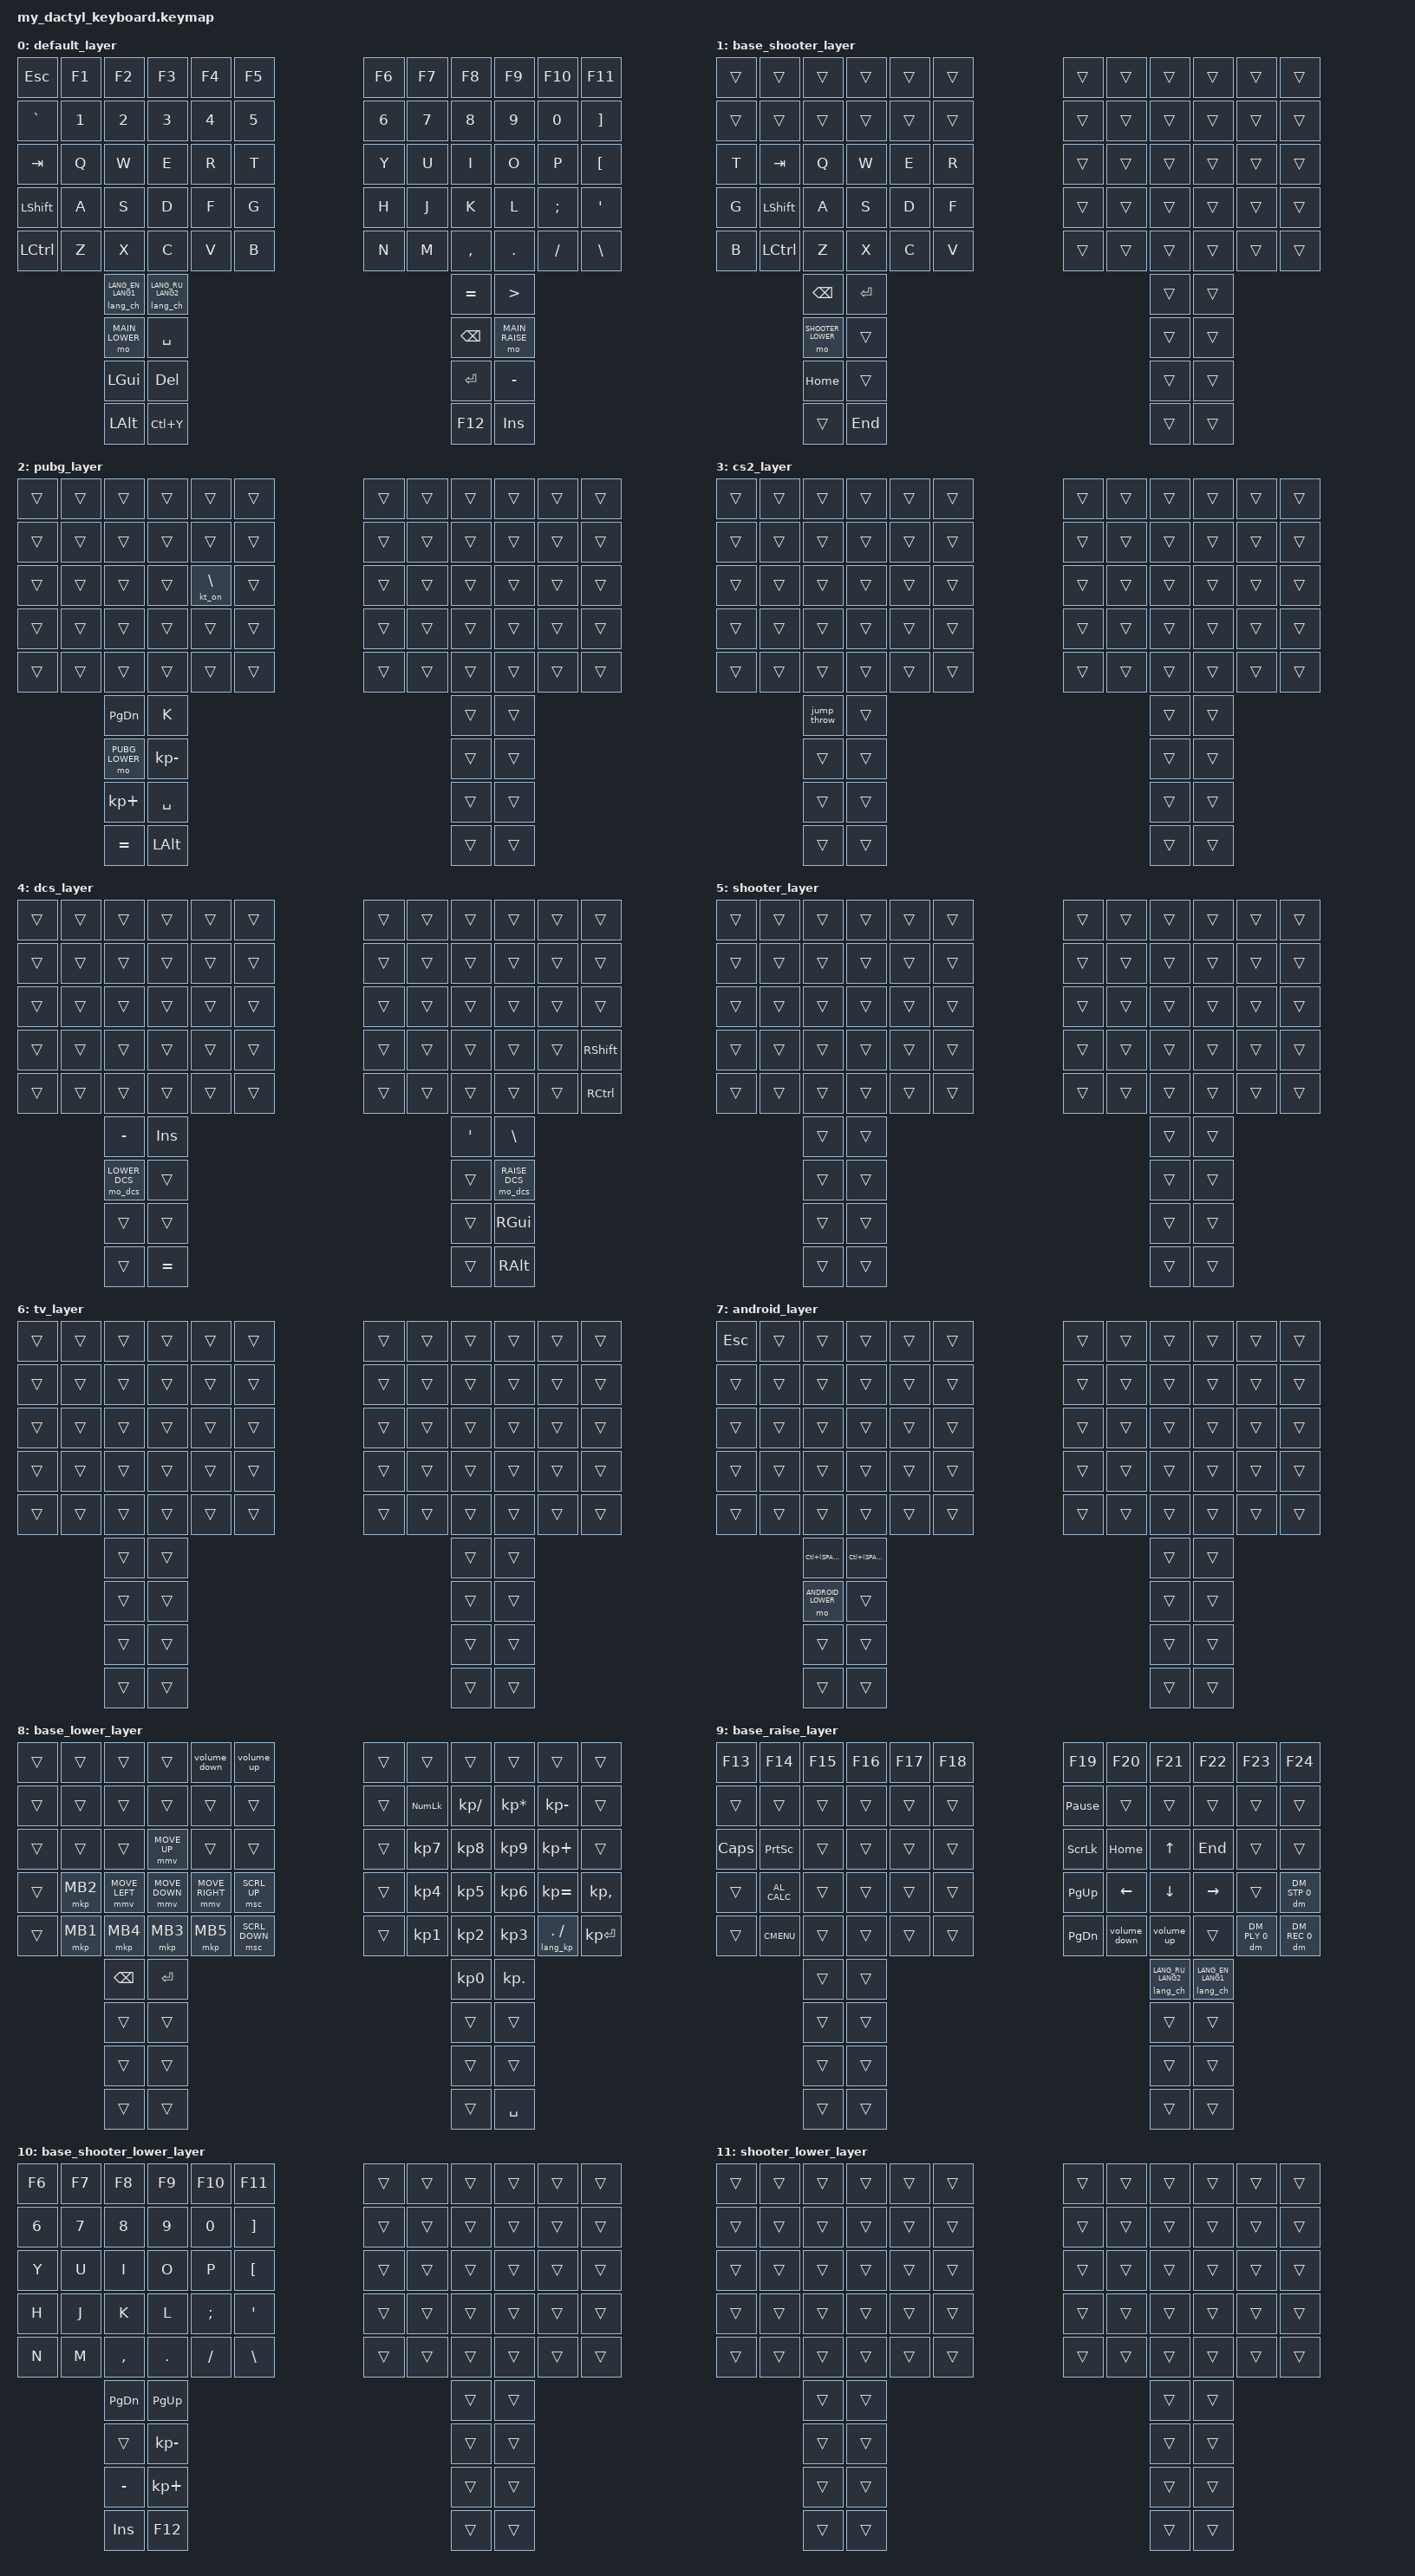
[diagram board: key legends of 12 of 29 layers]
/*
 * Copyright (c) 2020 The ZMK Contributors
 *
 * SPDX-License-Identifier: MIT
 */

#include <behaviors.dtsi>
#include <dt-bindings/zmk/keys.h>
#include <dt-bindings/zmk/bt.h>
#include <dt-bindings/zmk/rgb.h>
#include <dt-bindings/zmk/ext_power.h>
#include <dt-bindings/zmk/outputs.h>
#include <dt-bindings/zmk/backlight.h>
#include <dt-bindings/zmk/language.h>
#include <dt-bindings/zmk/dynamic_macro.h>

#define ZMK_POINTING_DEFAULT_MOVE_VAL 1500
#define ZMK_POINTING_DEFAULT_SCRL_VAL 40    // default: 10

#include <dt-bindings/zmk/pointing.h>

#define BASE                  0
#define BASE_SHOOTER          1
#define PUBG                  2
#define CS2                   3
#define DCS                   4
#define SHOOTER               5
#define TV_LAYER              6
#define ANDROID               7
#define LOWER                 8
#define RAISE                 9
#define BASE_SHOOTER_LOWER    10
#define SHOOTER_LOWER         11
#define MAIN_LOWER            12
#define MAIN_RAISE            13
#define PUBG_LOWER            14
#define TV_LOWER_LAYER        15
#define ANDROID_LOWER         16
#define LOWER_DCS             17
#define RAISE_DCS             18
#define RAISE_LOWER_DCS       19
#define RAISE_LOWER_DCS_ALT   20
#define RAISE_LOWER_DCS_GUI   21
#define RAISE_LOWER_DCS_CTRL  22
#define RAISE_LOWER_DCS_SHFT  23
#define RAISE_LOWER_DCS_CS    24
#define RAISE_LOWER_DCS_GA    25
#define SC2                   26
#define SC2_LOWER             27
#define ADJUST                28

/ {
    conditional_layers {
        compatible = "zmk,conditional-layers";
        adjust_layer {
            if-layers = <LOWER RAISE>;
            then-layer = <ADJUST>;
        };
        adjust_pubg_layer {
            if-layers = <PUBG_LOWER RAISE>;
            then-layer = <ADJUST>;
        };
        adjust_shooter_layer {
            if-layers = <SHOOTER_LOWER RAISE>;
            then-layer = <ADJUST>;
        };
        adjust_sc2_layer {
            if-layers = <SC2_LOWER RAISE>;
            then-layer = <ADJUST>;
        };
        lower_tv_layer {
            if-layers = <TV_LOWER_LAYER>;
            then-layer = <LOWER>;
        };
        lower_dcs_layer {
            if-layers = <LOWER_DCS>;
            then-layer = <LOWER>;
        };
        raise_dcs_layer {
            if-layers = <RAISE_DCS>;
            then-layer = <RAISE>;
        };
        lower_layer {
            if-layers = <MAIN_LOWER>;
            then-layer = <LOWER>;
        };
        android_lower_layer {
            if-layers = <ANDROID_LOWER>;
            then-layer = <LOWER>;
        };
        sc2_layer {
            if-layers = <SC2>;
            then-layer = <BASE_SHOOTER>;
        };
        sc2_lower_layer {
            if-layers = <SC2_LOWER>;
            then-layer = <BASE_SHOOTER_LOWER>;
        };
        raise_layer {
            if-layers = <MAIN_RAISE>;
            then-layer = <RAISE>;
        };
        pubg_layer {
            if-layers = <PUBG>;
            then-layer = <BASE_SHOOTER>;
        };
        cs2_layer {
            if-layers = <CS2>;
            then-layer = <BASE_SHOOTER>;
        };
        shooter_layer {
            if-layers = <SHOOTER>;
            then-layer = <BASE_SHOOTER>;
        };
        shooter_lower_layer {
            if-layers = <SHOOTER_LOWER>;
            then-layer = <BASE_SHOOTER_LOWER>;
        };
    };

    behaviors {
        hidiokp: hid_io_key_press {
          compatible = "zmk,behavior-hid-io-key-press";
          #binding-cells = <1>;
        };
        tog_on: toggle_layer_on_only {
            compatible = "zmk,behavior-toggle-layer";
            #binding-cells = <1>;
            display-name = "Toggle Layer On";
            toggle-mode = "on";
        };
        tog_off: toggle_layer_off_only {
            compatible = "zmk,behavior-toggle-layer";
            #binding-cells = <1>;
            display-name = "Toggle Layer Off";
            toggle-mode = "off";
        };
        kt_off: key_toggle_off_only {
            compatible = "zmk,behavior-key-toggle";
            #binding-cells = <1>;
            display-name = "Key Toggle Off";
            toggle-mode = "off";
        };
        kt_on: key_toggle_on_only {
            compatible = "zmk,behavior-key-toggle";
            #binding-cells = <1>;
            display-name = "Key Toggle On";
            toggle-mode = "on";
        };
        z2m: z2m {
            compatible = "zmk,behavior-zigbee-command";
            #binding-cells = <1>;
            display-name = "Zigbee command";
        };
        z2m_on: z2m_on {
            compatible = "zmk,behavior-zigbee-start";
            #binding-cells = <0>;
            display-name = "Start Zigbee";
        };
    };

    macros {
        hidlm: hidlm {
            compatible = "zmk,behavior-macro-two-param";
            wait-ms = <0>;
            tap-ms = <0>;
            #binding-cells = <2>;
            bindings
                = <&macro_param_1to1>
                , <&macro_press &mo MACRO_PLACEHOLDER>
                , <&macro_param_2to1>
                , <&macro_press &hidiokp MACRO_PLACEHOLDER>
                , <&macro_pause_for_release>
                , <&macro_param_2to1>
                , <&macro_release &hidiokp MACRO_PLACEHOLDER>
                , <&macro_param_1to1>
                , <&macro_release &mo MACRO_PLACEHOLDER>
                ;
        };
        skm: sticky_modifiers {
            compatible = "zmk,behavior-sticky-key";
            #binding-cells = <1>;
            bindings = <&kp>;
            release-after-ms = <2000>;
            ignore-modifiers;
        };
        sw_bl: sw_bl {
            compatible = "zmk,behavior-macro-one-param";
            #binding-cells = <1>;
            bindings
                = <&out OUT_BLE>
                , <&macro_param_1to2>
                , <&bt BT_SEL MACRO_PLACEHOLDER>
                ;
        };
        sw_bl1: sw_bl1 {
            compatible = "zmk,behavior-macro";
            #binding-cells = <0>;
            bindings
                = <&out OUT_BLE>
                , <&to BASE>
                , <&bt BT_SEL 0>
                ;
        };
        sw_bl2: sw_bl2 {
            compatible = "zmk,behavior-macro";
            #binding-cells = <0>;
            bindings
                = <&out OUT_BLE>
                , <&to ANDROID>
                , <&bt BT_SEL 1>
                ;
        };
        jump_throw: jump_throw {
            compatible = "zmk,behavior-macro";
            #binding-cells = <0>;
            bindings
                = <&macro_press &kp SPACE &kp F13 &kp F14>
                , <&macro_pause_for_release>
                , <&macro_release &kp SPACE &kp F13 &kp F14>
                ;
        };
        volume_up: volume_up {
            compatible = "zmk,behavior-macro";
            #binding-cells = <0>;
            bindings
                = <&macro_press &kp K_VOLUME_UP &kp C_VOLUME_UP>
                , <&macro_pause_for_release>
                , <&macro_release &kp K_VOLUME_UP &kp C_VOLUME_UP>
                ;
        };
        volume_down: volume_down {
            compatible = "zmk,behavior-macro";
            #binding-cells = <0>;
            bindings
                = <&macro_press &kp K_VOLUME_DOWN &kp C_VOLUME_DOWN>
                , <&macro_pause_for_release>
                , <&macro_release &kp K_VOLUME_DOWN &kp C_VOLUME_DOWN>
                ;
        };
        mo_dcs: parent_hold_dcs {
             compatible = "zmk,behavior-macro-one-param";
             #binding-cells = <1>;
             wait-ms = <0>;
             tap-ms = <0>;
             bindings
                 = <&macro_param_1to1>
                 , <&macro_press &mo MACRO_PLACEHOLDER>
                 , <&macro_pause_for_release>
                 , <&macro_tap &tog_off RAISE_LOWER_DCS &tog_off RAISE_LOWER_DCS_CTRL &tog_off RAISE_LOWER_DCS_SHFT &tog_off RAISE_LOWER_DCS_CS &tog_off RAISE_LOWER_DCS_GA &tog_off RAISE_LOWER_DCS_ALT &tog_off RAISE_LOWER_DCS_GUI>
                 , <&macro_param_1to1>
                 , <&macro_release &mo MACRO_PLACEHOLDER>
                 ;
        };
        lc_dcs: layer_choose_dcs {
             compatible = "zmk,behavior-macro-one-param";
             #binding-cells = <1>;
             wait-ms = <0>;
             tap-ms = <0>;
             bindings
                 = <&macro_tap &tog_off RAISE_LOWER_DCS_CTRL &tog_off RAISE_LOWER_DCS_SHFT &tog_off RAISE_LOWER_DCS_CS &tog_off RAISE_LOWER_DCS_GA &tog_off RAISE_LOWER_DCS_ALT &tog_off RAISE_LOWER_DCS_GUI>
                 , <&macro_param_1to1>
                 , <&macro_tap &tog_on MACRO_PLACEHOLDER>
                 ;
        };
        hidm: hidm {
              compatible = "zmk,behavior-macro-two-param";
              wait-ms = <20>;
              tap-ms = <20>;
              #binding-cells = <2>;
              bindings
                  = <&macro_param_1to1>
                  , <&macro_press &kp MACRO_PLACEHOLDER>
                  , <&macro_param_2to1>
                  , <&macro_press &hidiokp MACRO_PLACEHOLDER>
                  , <&macro_pause_for_release>
                  , <&macro_param_2to1>
                  , <&macro_release &hidiokp MACRO_PLACEHOLDER>
                  , <&macro_param_1to1>
                  , <&macro_release &kp MACRO_PLACEHOLDER>
                  ;
          };
        slm: sticky_layer_modifier {
            compatible = "zmk,behavior-macro-two-param";
            #binding-cells = <2>;

            wait-ms = <0>;
            tap-ms = <0>;

            bindings
                = <&macro_param_1to1>
                , <&sl MACRO_PLACEHOLDER>

                , <&macro_param_2to1>
                , <&sk MACRO_PLACEHOLDER>
                ;
        };
        sc2_second: sc2_second {
            compatible = "zmk,behavior-macro-one-param";
            #binding-cells = <1>;

            wait-ms = <20>;
            tap-ms = <20>;

            bindings
                = <&macro_param_1to1>
                , <&kp MACRO_PLACEHOLDER>
                , <&kp TAB>
                ;
        };
    };

    keymap {
        compatible = "zmk,keymap";

        default_layer {
            bindings = <
&kp ESC   &kp F1 &kp F2                 &kp F3                 &kp F4 &kp F5                    &kp F6 &kp F7 &kp F8    &kp F9         &kp F10  &kp F11
&kp GRAVE &kp N1 &kp N2                 &kp N3                 &kp N4 &kp N5                    &kp N6 &kp N7 &kp N8    &kp N9         &kp N0   &kp RBKT
&kp TAB   &kp Q  &kp W                  &kp E                  &kp R  &kp T                     &kp Y  &kp U  &kp I     &kp O          &kp P    &kp LBKT
&kp LSHFT &kp A  &kp S                  &kp D                  &kp F  &kp G                     &kp H  &kp J  &kp K     &kp L          &kp SEMI &kp SQT
&kp LCTRL &kp Z  &kp X                  &kp C                  &kp V  &kp B                     &kp N  &kp M  &kp COMMA &kp DOT        &kp FSLH &kp BSLH
                 &lang_ch LANG_EN LANG1 &lang_ch LANG_RU LANG2                                                &kp EQUAL &kp GT
                 &mo MAIN_LOWER         &kp SPACE                                                             &kp BSPC  &mo MAIN_RAISE
                 &kp LGUI               &kp DEL                                                               &kp RET   &kp MINUS
                 &kp LALT               &kp LC(Y)                                                             &kp F12   &kp INS
            >;
        };

        base_shooter_layer {
            bindings = <
&trans &trans    &trans            &trans  &trans &trans                    &trans &trans &trans &trans &trans &trans
&trans &trans    &trans            &trans  &trans &trans                    &trans &trans &trans &trans &trans &trans
&kp T  &kp TAB   &kp Q             &kp W   &kp E  &kp R                     &trans &trans &trans &trans &trans &trans
&kp G  &kp LSHFT &kp A             &kp S   &kp D  &kp F                     &trans &trans &trans &trans &trans &trans
&kp B  &kp LCTRL &kp Z             &kp X   &kp C  &kp V                     &trans &trans &trans &trans &trans &trans
                 &kp BSPC          &kp RET                                                &trans &trans
                 &mo SHOOTER_LOWER &trans                                                 &trans &trans
                 &kp HOME          &trans                                                 &trans &trans
                 &trans            &kp END                                                &trans &trans
            >;
        };

        pubg_layer {
            bindings = <
&trans &trans &trans         &trans       &trans      &trans                    &trans &trans &trans &trans &trans &trans
&trans &trans &trans         &trans       &trans      &trans                    &trans &trans &trans &trans &trans &trans
&trans &trans &trans         &trans       &kt_on BSLH &trans                    &trans &trans &trans &trans &trans &trans
&trans &trans &trans         &trans       &trans      &trans                    &trans &trans &trans &trans &trans &trans
&trans &trans &trans         &trans       &trans      &trans                    &trans &trans &trans &trans &trans &trans
              &kp PG_DN      &kp K                                                            &trans &trans
              &mo PUBG_LOWER &kp KP_MINUS                                                     &trans &trans
              &kp KP_PLUS    &kp SPACE                                                        &trans &trans
              &kp EQUAL      &kp LALT                                                         &trans &trans
            >;
        };

        cs2_layer {
            bindings = <
&trans &trans &trans      &trans &trans &trans                    &trans &trans &trans &trans &trans &trans
&trans &trans &trans      &trans &trans &trans                    &trans &trans &trans &trans &trans &trans
&trans &trans &trans      &trans &trans &trans                    &trans &trans &trans &trans &trans &trans
&trans &trans &trans      &trans &trans &trans                    &trans &trans &trans &trans &trans &trans
&trans &trans &trans      &trans &trans &trans                    &trans &trans &trans &trans &trans &trans
              &jump_throw &trans                                                &trans &trans
              &trans      &trans                                                &trans &trans
              &trans      &trans                                                &trans &trans
              &trans      &trans                                                &trans &trans
            >;
        };

        dcs_layer {
            bindings = <
&trans &trans &trans            &trans    &trans &trans                    &trans &trans &trans  &trans            &trans &trans
&trans &trans &trans            &trans    &trans &trans                    &trans &trans &trans  &trans            &trans &trans
&trans &trans &trans            &trans    &trans &trans                    &trans &trans &trans  &trans            &trans &trans
&trans &trans &trans            &trans    &trans &trans                    &trans &trans &trans  &trans            &trans &kp RSHFT
&trans &trans &trans            &trans    &trans &trans                    &trans &trans &trans  &trans            &trans &kp RCTRL
              &kp MINUS         &kp INS                                                  &kp SQT &kp BSLH
              &mo_dcs LOWER_DCS &trans                                                   &trans  &mo_dcs RAISE_DCS
              &trans            &trans                                                   &trans  &kp RGUI
              &trans            &kp EQUAL                                                &trans  &kp RALT
            >;
        };

        shooter_layer {
            bindings = <
&trans &trans &trans &trans &trans &trans                    &trans &trans &trans &trans &trans &trans
&trans &trans &trans &trans &trans &trans                    &trans &trans &trans &trans &trans &trans
&trans &trans &trans &trans &trans &trans                    &trans &trans &trans &trans &trans &trans
&trans &trans &trans &trans &trans &trans                    &trans &trans &trans &trans &trans &trans
&trans &trans &trans &trans &trans &trans                    &trans &trans &trans &trans &trans &trans
              &trans &trans                                                &trans &trans
              &trans &trans                                                &trans &trans
              &trans &trans                                                &trans &trans
              &trans &trans                                                &trans &trans
            >;
        };

        tv_layer {
            bindings = <
&trans &trans &trans &trans &trans &trans                    &trans &trans &trans &trans &trans &trans
&trans &trans &trans &trans &trans &trans                    &trans &trans &trans &trans &trans &trans
&trans &trans &trans &trans &trans &trans                    &trans &trans &trans &trans &trans &trans
&trans &trans &trans &trans &trans &trans                    &trans &trans &trans &trans &trans &trans
&trans &trans &trans &trans &trans &trans                    &trans &trans &trans &trans &trans &trans
              &trans &trans                                                &trans &trans
              &trans &trans                                                &trans &trans
              &trans &trans                                                &trans &trans
              &trans &trans                                                &trans &trans
            >;
        };

        android_layer {
            bindings = <
&kp ESC &trans &trans            &trans          &trans &trans                    &trans &trans &trans &trans &trans &trans
&trans  &trans &trans            &trans          &trans &trans                    &trans &trans &trans &trans &trans &trans
&trans  &trans &trans            &trans          &trans &trans                    &trans &trans &trans &trans &trans &trans
&trans  &trans &trans            &trans          &trans &trans                    &trans &trans &trans &trans &trans &trans
&trans  &trans &trans            &trans          &trans &trans                    &trans &trans &trans &trans &trans &trans
               &kp LC((SPACE))   &kp LC((SPACE))                                                &trans &trans
               &mo ANDROID_LOWER &trans                                                         &trans &trans
               &trans            &trans                                                         &trans &trans
               &trans            &trans                                                         &trans &trans
            >;
        };

        base_lower_layer {
            bindings = <
&trans &trans   &trans         &trans         &volume_down    &volume_up                        &trans &trans     &trans        &trans          &trans            &trans
&trans &trans   &trans         &trans         &trans          &trans                            &trans &kp KP_NUM &kp KP_DIVIDE &kp KP_MULTIPLY &kp KP_MINUS      &trans
&trans &trans   &trans         &mmv MOVE_UP   &trans          &trans                            &trans &kp KP_N7  &kp KP_N8     &kp KP_N9       &kp KP_PLUS       &trans
&trans &mkp MB2 &mmv MOVE_LEFT &mmv MOVE_DOWN &mmv MOVE_RIGHT &msc SCRL_UP                      &trans &kp KP_N4  &kp KP_N5     &kp KP_N6       &kp KP_EQUAL      &kp KP_COMMA
&trans &mkp MB1 &mkp MB4       &mkp MB3       &mkp MB5        &msc SCRL_DOWN                    &trans &kp KP_N1  &kp KP_N2     &kp KP_N3       &lang_kp DOT FSLH &kp KP_ENTER
                &kp BSPC       &kp RET                                                                            &kp KP_N0     &kp KP_DOT
                &trans         &trans                                                                             &trans        &trans
                &trans         &trans                                                                             &trans        &trans
                &trans         &trans                                                                             &trans        &kp SPACE
            >;
        };

        base_raise_layer {
            bindings = <
&kp F13  &kp F14       &kp F15 &kp F16 &kp F17 &kp F18                    &kp F19         &kp F20      &kp F21                &kp F22                &kp F23      &kp F24
&trans   &trans        &trans  &trans  &trans  &trans                     &kp PAUSE_BREAK &trans       &trans                 &trans                 &trans       &trans
&kp CAPS &kp PSCRN     &trans  &trans  &trans  &trans                     &kp SCROLLLOCK  &kp HOME     &kp UP                 &kp END                &trans       &trans
&trans   &kp C_AL_CALC &trans  &trans  &trans  &trans                     &kp PG_UP       &kp LEFT     &kp DOWN               &kp RIGHT              &trans       &dm DM_STP 0
&trans   &kp K_CMENU   &trans  &trans  &trans  &trans                     &kp PG_DN       &volume_down &volume_up             &trans                 &dm DM_PLY 0 &dm DM_REC 0
                       &trans  &trans                                                                  &lang_ch LANG_RU LANG2 &lang_ch LANG_EN LANG1
                       &trans  &trans                                                                  &trans                 &trans
                       &trans  &trans                                                                  &trans                 &trans
                       &trans  &trans                                                                  &trans                 &trans
            >;
        };

        base_shooter_lower_layer {
            bindings = <
&kp F6 &kp F7 &kp F8    &kp F9       &kp F10  &kp F11                     &trans &trans &trans &trans &trans &trans
&kp N6 &kp N7 &kp N8    &kp N9       &kp N0   &kp RBKT                    &trans &trans &trans &trans &trans &trans
&kp Y  &kp U  &kp I     &kp O        &kp P    &kp LBKT                    &trans &trans &trans &trans &trans &trans
&kp H  &kp J  &kp K     &kp L        &kp SEMI &kp SQT                     &trans &trans &trans &trans &trans &trans
&kp N  &kp M  &kp COMMA &kp DOT      &kp FSLH &kp BSLH                    &trans &trans &trans &trans &trans &trans
              &kp PG_DN &kp PG_UP                                                       &trans &trans
              &trans    &kp KP_MINUS                                                    &trans &trans
              &kp MINUS &kp KP_PLUS                                                     &trans &trans
              &kp INS   &kp F12                                                         &trans &trans
            >;
        };

        shooter_lower_layer {
            bindings = <
&trans &trans &trans &trans &trans &trans                    &trans &trans &trans &trans &trans &trans
&trans &trans &trans &trans &trans &trans                    &trans &trans &trans &trans &trans &trans
&trans &trans &trans &trans &trans &trans                    &trans &trans &trans &trans &trans &trans
&trans &trans &trans &trans &trans &trans                    &trans &trans &trans &trans &trans &trans
&trans &trans &trans &trans &trans &trans                    &trans &trans &trans &trans &trans &trans
              &trans &trans                                                &trans &trans
              &trans &trans                                                &trans &trans
              &trans &trans                                                &trans &trans
              &trans &trans                                                &trans &trans
            >;
        };

        lower_layer {
            bindings = <
&trans &trans &trans &trans &trans &trans                    &trans &trans &trans &trans &trans &trans
&trans &trans &trans &trans &trans &trans                    &trans &trans &trans &trans &trans &trans
&trans &trans &trans &trans &trans &trans                    &trans &trans &trans &trans &trans &trans
&trans &trans &trans &trans &trans &trans                    &trans &trans &trans &trans &trans &trans
&trans &trans &trans &trans &trans &trans                    &trans &trans &trans &trans &trans &trans
              &trans &trans                                                &trans &trans
              &trans &trans                                                &trans &trans
              &trans &trans                                                &trans &trans
              &trans &trans                                                &trans &trans
            >;
        };

        raise_layer {
            bindings = <
&trans &trans &trans &trans &trans &trans                    &trans &trans &trans &trans &trans &trans
&trans &trans &trans &trans &trans &trans                    &trans &trans &trans &trans &trans &trans
&trans &trans &trans &trans &trans &trans                    &trans &trans &trans &trans &trans &trans
&trans &trans &trans &trans &trans &trans                    &trans &trans &trans &trans &trans &trans
&trans &trans &trans &trans &trans &trans                    &trans &trans &trans &trans &trans &trans
              &trans &trans                                                &trans &trans
              &trans &trans                                                &trans &trans
              &trans &trans                                                &trans &trans
              &trans &trans                                                &trans &trans
            >;
        };

        pubg_lower_layer {
            bindings = <
&kp F6    &kp F7  &kp F8 &kp F9        &kp F10 &kp F12                      &trans &trans &trans &trans &trans &trans
&kp MINUS &kp N6  &kp N7 &kp N8        &kp N9  &kp N0                       &trans &trans &trans &trans &trans &trans
&kp P     &kp DEL &kp Y  &trans        &kp I   &kp O                        &trans &trans &trans &trans &trans &trans
&kp U     &trans  &trans &trans        &trans  &kp L                        &trans &trans &trans &trans &trans &trans
&kp INS   &trans  &kp N  &kp M         &kp END &kp PG_UP                    &trans &trans &trans &trans &trans &trans
                  &kp J  &kp H                                                            &trans &trans
                  &trans &kp KP_DIVIDE                                                    &trans &trans
                  &trans &kp HOME                                                         &trans &trans
                  &trans &trans                                                           &trans &trans
            >;
        };

        tv_lower_layer {
            bindings = <
&trans &trans &trans &trans &trans &trans                    &trans &trans &trans &trans &trans &trans
&trans &trans &trans &trans &trans &trans                    &trans &trans &trans &trans &trans &trans
&trans &trans &trans &trans &trans &trans                    &trans &trans &trans &trans &trans &trans
&trans &trans &trans &trans &trans &trans                    &trans &trans &trans &trans &trans &trans
&trans &trans &trans &trans &trans &trans                    &trans &trans &trans &trans &trans &trans
              &trans &trans                                                &trans &trans
              &trans &trans                                                &trans &trans
              &trans &trans                                                &trans &trans
              &trans &trans                                                &trans &trans
            >;
        };

        android_lower_layer {
            bindings = <
&kp C_AC_HOME &trans &trans &trans &trans &trans                    &trans &trans &trans &trans &trans &trans
&trans        &trans &trans &trans &trans &trans                    &trans &trans &trans &trans &trans &trans
&trans        &trans &trans &trans &trans &trans                    &trans &trans &trans &trans &trans &trans
&trans        &trans &trans &trans &trans &trans                    &trans &trans &trans &trans &trans &trans
&trans        &trans &trans &trans &trans &trans                    &trans &trans &trans &trans &trans &trans
                     &trans &trans                                                &trans &trans
                     &trans &trans                                                &trans &trans
                     &trans &trans                                                &trans &trans
                     &trans &trans                                                &trans &trans
            >;
        };

        dcs_lower_layer {
            bindings = <
&lc_dcs RAISE_LOWER_DCS &lc_dcs RAISE_LOWER_DCS_CS &lc_dcs  RAISE_LOWER_DCS_GA &trans &lc_dcs RAISE_LOWER_DCS_GUI &lc_dcs RAISE_LOWER_DCS_ALT                    &trans &trans &trans &trans   &trans       &trans
&trans                  &trans                     &trans                      &trans &trans                      &trans                                         &trans &trans &trans &trans   &trans       &trans
&trans                  &trans                     &trans                      &trans &trans                      &trans                                         &trans &trans &trans &trans   &trans       &trans
&trans                  &trans                     &trans                      &trans &trans                      &trans                                         &trans &trans &trans &trans   &kp KP_COMMA &kp RSHFT
&trans                  &trans                     &trans                      &trans &trans                      &trans                                         &trans &trans &trans &trans   &kp KP_ENTER &kp RCTRL
                                                   &trans                      &trans                                                                                          &trans &trans
                                                   &trans                      &trans                                                                                          &trans &trans
                                                   &trans                      &trans                                                                                          &trans &kp RGUI
                                                   &trans                      &trans                                                                                          &trans &kp RALT
            >;
        };

        dcs_raise_layer {
            bindings = <
&trans &trans &trans &trans &trans &trans                    &lc_dcs RAISE_LOWER_DCS_ALT &lc_dcs RAISE_LOWER_DCS_GUI &trans    &lc_dcs  RAISE_LOWER_DCS_GA &lc_dcs RAISE_LOWER_DCS_CS &lc_dcs RAISE_LOWER_DCS
&trans &trans &trans &trans &trans &trans                    &trans                      &trans                      &trans    &trans                      &trans                     &trans
&trans &trans &trans &trans &trans &trans                    &trans                      &trans                      &trans    &trans                      &trans                     &trans
&trans &trans &trans &trans &trans &trans                    &trans                      &trans                      &trans    &trans                      &trans                     &kp RSHFT
&trans &trans &trans &trans &trans &trans                    &trans                      &trans                      &trans    &trans                      &trans                     &kp RCTRL
              &trans &trans                                                                                          &skm RALT &skm RGUI
              &trans &trans                                                                                          &trans    &trans
              &trans &trans                                                                                          &trans    &kp RGUI
              &trans &trans                                                                                          &trans    &kp RALT
            >;
        };

        dcs_raise_lower {
            bindings = <
&hidm LC(RCTRL) 7            &hidm LC(RCTRL) 6  &hidm LC(RCTRL) 5  &hidm LC(RCTRL) 4  &hidm LC(RCTRL) 3  &hidm LC(RCTRL) 2                     &hidiokp 2  &hidiokp 3  &hidiokp 4  &hidiokp 5  &hidiokp 6  &hidiokp 7
&hidm LC(RCTRL) 13           &hidm LC(RCTRL) 12 &hidm LC(RCTRL) 11 &hidm LC(RCTRL) 10 &hidm LC(RCTRL) 9  &hidm LC(RCTRL) 8                     &hidiokp 8  &hidiokp 9  &hidiokp 10 &hidiokp 11 &hidiokp 12 &hidiokp 13
&hidm LC(RCTRL) 19           &hidm LC(RCTRL) 18 &hidm LC(RCTRL) 17 &hidm LC(RCTRL) 16 &hidm LC(RCTRL) 15 &hidm LC(RCTRL) 14                    &hidiokp 14 &hidiokp 15 &hidiokp 16 &hidiokp 17 &hidiokp 18 &hidiokp 19
&lc_dcs RAISE_LOWER_DCS_SHFT &hidm LC(RCTRL) 24 &hidm LC(RCTRL) 23 &hidm LC(RCTRL) 22 &hidm LC(RCTRL) 21 &hidm LC(RCTRL) 20                    &hidiokp 20 &hidiokp 21 &hidiokp 22 &hidiokp 23 &hidiokp 24 &lc_dcs RAISE_LOWER_DCS_SHFT
&lc_dcs RAISE_LOWER_DCS_CTRL &hidm LC(RCTRL) 29 &hidm LC(RCTRL) 28 &hidm LC(RCTRL) 27 &hidm LC(RCTRL) 26 &hidm LC(RCTRL) 25                    &hidiokp 25 &hidiokp 26 &hidiokp 27 &hidiokp 28 &hidiokp 29 &lc_dcs RAISE_LOWER_DCS_CTRL
                                                &hidm LC(RCTRL) 31 &hidm LC(RCTRL) 30                                                                                  &hidiokp 30 &hidiokp 31
                                                &trans             &trans                                                                                              &trans      &trans
                                                &trans             &trans                                                                                              &trans      &trans
                                                &trans             &trans                                                                                              &trans      &trans
            >;
        };

        dcs_raise_lower_alt {
            bindings = <
&hidm LALT 7                 &hidm LALT 6  &hidm LALT 5  &hidm LALT 4  &hidm LALT 3  &hidm LALT 2                     &hidm RALT 2  &hidm RALT 3  &hidm RALT 4  &hidm RALT 5  &hidm RALT 6  &hidm RALT 7
&hidm LALT 13                &hidm LALT 12 &hidm LALT 11 &hidm LALT 10 &hidm LALT 9  &hidm LALT 8                     &hidm RALT 8  &hidm RALT 9  &hidm RALT 10 &hidm RALT 11 &hidm RALT 12 &hidm RALT 13
&hidm LALT 19                &hidm LALT 18 &hidm LALT 17 &hidm LALT 16 &hidm LALT 15 &hidm LALT 14                    &hidm RALT 14 &hidm RALT 15 &hidm RALT 16 &hidm RALT 17 &hidm RALT 18 &hidm RALT 19
&lc_dcs RAISE_LOWER_DCS_SHFT &hidm LALT 24 &hidm LALT 23 &hidm LALT 22 &hidm LALT 21 &hidm LALT 20                    &hidm RALT 20 &hidm RALT 21 &hidm RALT 22 &hidm RALT 23 &hidm RALT 24 &lc_dcs RAISE_LOWER_DCS_SHFT
&lc_dcs RAISE_LOWER_DCS_CTRL &hidm LALT 29 &hidm LALT 28 &hidm LALT 27 &hidm LALT 26 &hidm LALT 25                    &hidm RALT 25 &hidm RALT 26 &hidm RALT 27 &hidm RALT 28 &hidm RALT 29 &lc_dcs RAISE_LOWER_DCS_CTRL
                                           &hidm LALT 31 &hidm LALT 30                                                                            &hidm RALT 30 &hidm RALT 31
                                           &trans        &trans                                                                                   &trans        &trans
                                           &trans        &trans                                                                                   &trans        &trans
                                           &trans        &trans                                                                                   &trans        &trans
            >;
        };

        dcs_raise_lower_gui {
            bindings = <
&hidm LGUI 7                 &hidm LGUI 6  &hidm LGUI 5  &hidm LGUI 4  &hidm LGUI 3  &hidm LGUI 2                     &hidm RGUI 2  &hidm RGUI 3  &hidm RGUI 4  &hidm RGUI 5  &hidm RGUI 6  &hidm RGUI 7
&hidm LGUI 13                &hidm LGUI 12 &hidm LGUI 11 &hidm LGUI 10 &hidm LGUI 9  &hidm LGUI 8                     &hidm RGUI 8  &hidm RGUI 9  &hidm RGUI 10 &hidm RGUI 11 &hidm RGUI 12 &hidm RGUI 13
&hidm LGUI 19                &hidm LGUI 18 &hidm LGUI 17 &hidm LGUI 16 &hidm LGUI 15 &hidm LGUI 14                    &hidm RGUI 14 &hidm RGUI 15 &hidm RGUI 16 &hidm RGUI 17 &hidm RGUI 18 &hidm RGUI 19
&lc_dcs RAISE_LOWER_DCS_SHFT &hidm LGUI 24 &hidm LGUI 23 &hidm LGUI 22 &hidm LGUI 21 &hidm LGUI 20                    &hidm RGUI 20 &hidm RGUI 21 &hidm RGUI 22 &hidm RGUI 23 &hidm RGUI 24 &lc_dcs RAISE_LOWER_DCS_SHFT
&lc_dcs RAISE_LOWER_DCS_CTRL &hidm LGUI 29 &hidm LGUI 28 &hidm LGUI 27 &hidm LGUI 26 &hidm LGUI 25                    &hidm RGUI 25 &hidm RGUI 26 &hidm RGUI 27 &hidm RGUI 28 &hidm RGUI 29 &lc_dcs RAISE_LOWER_DCS_CTRL
                                           &hidm LGUI 31 &hidm LGUI 30                                                                            &hidm RGUI 30 &hidm RGUI 31
                                           &trans        &trans                                                                                   &trans        &trans
                                           &trans        &trans                                                                                   &trans        &trans
                                           &trans        &trans                                                                                   &trans        &trans
            >;
        };

        dcs_raise_lower_ctrl {
            bindings = <
&hidm LCTRL 7                &hidm LCTRL 6  &hidm LCTRL 5  &hidm LCTRL 4  &hidm LCTRL 3  &hidm LCTRL 2                     &hidm RCTRL 2  &hidm RCTRL 3  &hidm RCTRL 4  &hidm RCTRL 5  &hidm RCTRL 6  &hidm RCTRL 7
&hidm LCTRL 13               &hidm LCTRL 12 &hidm LCTRL 11 &hidm LCTRL 10 &hidm LCTRL 9  &hidm LCTRL 8                     &hidm RCTRL 8  &hidm RCTRL 9  &hidm RCTRL 10 &hidm RCTRL 11 &hidm RCTRL 12 &hidm RCTRL 13
&hidm LCTRL 19               &hidm LCTRL 18 &hidm LCTRL 17 &hidm LCTRL 16 &hidm LCTRL 15 &hidm LCTRL 14                    &hidm RCTRL 14 &hidm RCTRL 15 &hidm RCTRL 16 &hidm RCTRL 17 &hidm RCTRL 18 &hidm RCTRL 19
&lc_dcs RAISE_LOWER_DCS_SHFT &hidm LCTRL 24 &hidm LCTRL 23 &hidm LCTRL 22 &hidm LCTRL 21 &hidm LCTRL 20                    &hidm RCTRL 20 &hidm RCTRL 21 &hidm RCTRL 22 &hidm RCTRL 23 &hidm RCTRL 24 &lc_dcs RAISE_LOWER_DCS_SHFT
&lc_dcs RAISE_LOWER_DCS_CTRL &hidm LCTRL 29 &hidm LCTRL 28 &hidm LCTRL 27 &hidm LCTRL 26 &hidm LCTRL 25                    &hidm RCTRL 25 &hidm RCTRL 26 &hidm RCTRL 27 &hidm RCTRL 28 &hidm RCTRL 29 &lc_dcs RAISE_LOWER_DCS_CTRL
                                            &hidm LCTRL 31 &hidm LCTRL 30                                                                                &hidm RCTRL 30 &hidm RCTRL 31
                                            &trans         &trans                                                                                        &trans         &trans
                                            &trans         &trans                                                                                        &trans         &trans
                                            &trans         &trans                                                                                        &trans         &trans
            >;
        };

        dcs_raise_lower_shft {
            bindings = <
&hidm LSHFT 7                &hidm LSHFT 6  &hidm LSHFT 5  &hidm LSHFT 4  &hidm LSHFT 3  &hidm LSHFT 2                     &hidm RSHFT 2  &hidm RSHFT 3  &hidm RSHFT 4  &hidm RSHFT 5  &hidm RSHFT 6  &hidm RSHFT 7
&hidm LSHFT 13               &hidm LSHFT 12 &hidm LSHFT 11 &hidm LSHFT 10 &hidm LSHFT 9  &hidm LSHFT 8                     &hidm RSHFT 8  &hidm RSHFT 9  &hidm RSHFT 10 &hidm RSHFT 11 &hidm RSHFT 12 &hidm RSHFT 13
&hidm LSHFT 19               &hidm LSHFT 18 &hidm LSHFT 17 &hidm LSHFT 16 &hidm LSHFT 15 &hidm LSHFT 14                    &hidm RSHFT 14 &hidm RSHFT 15 &hidm RSHFT 16 &hidm RSHFT 17 &hidm RSHFT 18 &hidm RSHFT 19
&lc_dcs RAISE_LOWER_DCS_SHFT &hidm LSHFT 24 &hidm LSHFT 23 &hidm LSHFT 22 &hidm LSHFT 21 &hidm LSHFT 20                    &hidm RSHFT 20 &hidm RSHFT 21 &hidm RSHFT 22 &hidm RSHFT 23 &hidm RSHFT 24 &lc_dcs RAISE_LOWER_DCS_SHFT
&lc_dcs RAISE_LOWER_DCS_CTRL &hidm LSHFT 29 &hidm LSHFT 28 &hidm LSHFT 27 &hidm LSHFT 26 &hidm LSHFT 25                    &hidm RSHFT 25 &hidm RSHFT 26 &hidm RSHFT 27 &hidm RSHFT 28 &hidm RSHFT 29 &lc_dcs RAISE_LOWER_DCS_CTRL
                                            &hidm LSHFT 31 &hidm LSHFT 30                                                                                &hidm RSHFT 30 &hidm RSHFT 31
                                            &trans         &trans                                                                                        &trans         &trans
                                            &trans         &trans                                                                                        &trans         &trans
                                            &trans         &trans                                                                                        &trans         &trans
            >;
        };

        dcs_raise_lower_ctrl_shft {
            bindings = <
&hidm LC(LSHFT) 7            &hidm LC(LSHFT) 6  &hidm LC(LSHFT) 5  &hidm LC(LSHFT) 4  &hidm LC(LSHFT) 3  &hidm LC(LSHFT) 2                     &hidm RC(RSHFT) 2  &hidm RC(RSHFT) 3  &hidm RC(RSHFT) 4  &hidm RC(RSHFT) 5  &hidm RC(RSHFT) 6  &hidm RC(RSHFT) 7
&hidm LC(LSHFT) 13           &hidm LC(LSHFT) 12 &hidm LC(LSHFT) 11 &hidm LC(LSHFT) 10 &hidm LC(LSHFT) 9  &hidm LC(LSHFT) 8                     &hidm RC(RSHFT) 8  &hidm RC(RSHFT) 9  &hidm RC(RSHFT) 10 &hidm RC(RSHFT) 11 &hidm RC(RSHFT) 12 &hidm RC(RSHFT) 13
&hidm LC(LSHFT) 19           &hidm LC(LSHFT) 18 &hidm LC(LSHFT) 17 &hidm LC(LSHFT) 16 &hidm LC(LSHFT) 15 &hidm LC(LSHFT) 14                    &hidm RC(RSHFT) 14 &hidm RC(RSHFT) 15 &hidm RC(RSHFT) 16 &hidm RC(RSHFT) 17 &hidm RC(RSHFT) 18 &hidm RC(RSHFT) 19
&lc_dcs RAISE_LOWER_DCS_SHFT &hidm LC(LSHFT) 24 &hidm LC(LSHFT) 23 &hidm LC(LSHFT) 22 &hidm LC(LSHFT) 21 &hidm LC(LSHFT) 20                    &hidm RC(RSHFT) 20 &hidm RC(RSHFT) 21 &hidm RC(RSHFT) 22 &hidm RC(RSHFT) 23 &hidm RC(RSHFT) 24 &lc_dcs RAISE_LOWER_DCS_SHFT
&lc_dcs RAISE_LOWER_DCS_CTRL &hidm LC(LSHFT) 29 &hidm LC(LSHFT) 28 &hidm LC(LSHFT) 27 &hidm LC(LSHFT) 26 &hidm LC(LSHFT) 25                    &hidm RC(RSHFT) 25 &hidm RC(RSHFT) 26 &hidm RC(RSHFT) 27 &hidm RC(RSHFT) 28 &hidm RC(RSHFT) 29 &lc_dcs RAISE_LOWER_DCS_CTRL
                                                &hidm LC(LSHFT) 31 &hidm LC(LSHFT) 30                                                                                                &hidm RC(RSHFT) 30 &hidm RC(RSHFT) 31
                                                &trans             &trans                                                                                                            &trans             &trans
                                                &trans             &trans                                                                                                            &trans             &trans
                                                &trans             &trans                                                                                                            &trans             &trans
            >;
        };

        dcs_raise_lower_gui_alt {
            bindings = <
&hidm LG(LALT) 7             &hidm LG(LALT) 6  &hidm LG(LALT) 5  &hidm LG(LALT) 4  &hidm LG(LALT) 3  &hidm LG(LALT) 2                     &hidm RG(RALT) 2  &hidm RG(RALT) 3  &hidm RG(RALT) 4  &hidm RG(RALT) 5  &hidm RG(RALT) 6  &hidm RG(RALT) 7
&hidm LG(LALT) 13            &hidm LG(LALT) 12 &hidm LG(LALT) 11 &hidm LG(LALT) 10 &hidm LG(LALT) 9  &hidm LG(LALT) 8                     &hidm RG(RALT) 8  &hidm RG(RALT) 9  &hidm RG(RALT) 10 &hidm RG(RALT) 11 &hidm RG(RALT) 12 &hidm RG(RALT) 13
&hidm LG(LALT) 19            &hidm LG(LALT) 18 &hidm LG(LALT) 17 &hidm LG(LALT) 16 &hidm LG(LALT) 15 &hidm LG(LALT) 14                    &hidm RG(RALT) 14 &hidm RG(RALT) 15 &hidm RG(RALT) 16 &hidm RG(RALT) 17 &hidm RG(RALT) 18 &hidm RG(RALT) 19
&lc_dcs RAISE_LOWER_DCS_SHFT &hidm LG(LALT) 24 &hidm LG(LALT) 23 &hidm LG(LALT) 22 &hidm LG(LALT) 21 &hidm LG(LALT) 20                    &hidm RG(RALT) 20 &hidm RG(RALT) 21 &hidm RG(RALT) 22 &hidm RG(RALT) 23 &hidm RG(RALT) 24 &lc_dcs RAISE_LOWER_DCS_SHFT
&lc_dcs RAISE_LOWER_DCS_CTRL &hidm LG(LALT) 29 &hidm LG(LALT) 28 &hidm LG(LALT) 27 &hidm LG(LALT) 26 &hidm LG(LALT) 25                    &hidm RG(RALT) 25 &hidm RG(RALT) 26 &hidm RG(RALT) 27 &hidm RG(RALT) 28 &hidm RG(RALT) 29 &lc_dcs RAISE_LOWER_DCS_CTRL
                                               &hidm LG(LALT) 31 &hidm LG(LALT) 30                                                                                            &hidm RG(RALT) 30 &hidm RG(RALT) 31
                                               &trans            &trans                                                                                                       &trans            &trans
                                               &trans            &trans                                                                                                       &trans            &trans
                                               &trans            &trans                                                                                                       &trans            &trans
            >;
        };

        sc2_layer {
            bindings = <
&trans &trans &trans        &trans &trans &trans                    &trans &trans &trans &trans &trans &trans
&trans &trans &trans        &trans &trans &trans                    &trans &trans &trans &trans &trans &trans
&trans &trans &trans        &trans &trans &trans                    &trans &trans &trans &trans &trans &trans
&trans &trans &trans        &trans &trans &trans                    &trans &trans &trans &trans &trans &trans
&trans &trans &trans        &trans &trans &trans                    &trans &trans &trans &trans &trans &trans
              &kp N6        &kp N7                                                &trans &trans
              &mo SC2_LOWER &kp N                                                 &trans &trans
              &kp LALT      &kp N8                                                &trans &trans
              &kp N0        &kp N9                                                &trans &trans
            >;
        };

        sc2_lower_layer {
            bindings = <
&kp F10   &kp F6         &kp F7         &kp F8         &kp F9         &kp F11                           &trans &trans &trans &trans &trans &trans
&kp DEL   &sc2_second N1 &sc2_second N2 &sc2_second N3 &sc2_second N4 &sc2_second N5                    &trans &trans &trans &trans &trans &trans
&kp Y     &kp U          &kp I          &kp O          &kp P          &kp LBKT                          &trans &trans &trans &trans &trans &trans
&kp H     &kp LSHFT      &kp J          &kp K          &kp L          &kp SEMI                          &trans &trans &trans &trans &trans &trans
&kp SPACE &kp LCTRL      &kp M          &kp COMMA      &kp DOT        &kp FSLH                          &trans &trans &trans &trans &trans &trans
                         &sc2_second N6 &sc2_second N7                                                                &trans &trans
                         &trans         &kp KP_MINUS                                                                  &trans &trans
                         &kp LALT       &kp KP_PLUS                                                                   &trans &trans
                         &kp INS        &kp F12                                                                       &trans &trans
            >;
        };

        adjust_layer {
            bindings = <
&none        &none         &none         &bt BT_DISC 2 &none         &none                            &none         &none         &none         &none         &none         &none
&out OUT_BLE &sw_bl1       &sw_bl2       &sw_bl 2      &sw_bl 3      &sw_bl 4                         &sw_bl 5      &sw_bl 6      &sw_bl 7      &sw_bl 8      &sw_bl 9      &out OUT_USB
&none        &bt BT_DISC 0 &bt BT_DISC 1 &bt BT_DISC 2 &bt BT_DISC 3 &bt BT_DISC 4                    &bt BT_DISC 5 &bt BT_DISC 6 &bt BT_DISC 7 &bt BT_DISC 8 &bt BT_DISC 9 &none
&to ANDROID  &to DCS       &to CS2       &to SC2       &none         &none                            &z2m 0        &z2m 1        &z2m 2        &none         &none         &none
&to BASE     &to SHOOTER   &to PUBG      &none         &none         &none                            &z2m 255      &none         &none         &none         &none         &bt BT_CLR
                           &none         &none                                                                                    &none         &none
                           &none         &none                                                                                    &none         &none
                           &none         &none                                                                                    &none         &none
                           &sys_reset    &bootloader                                                                              &bootloader   &sys_reset
            >;
        };
    };
};
